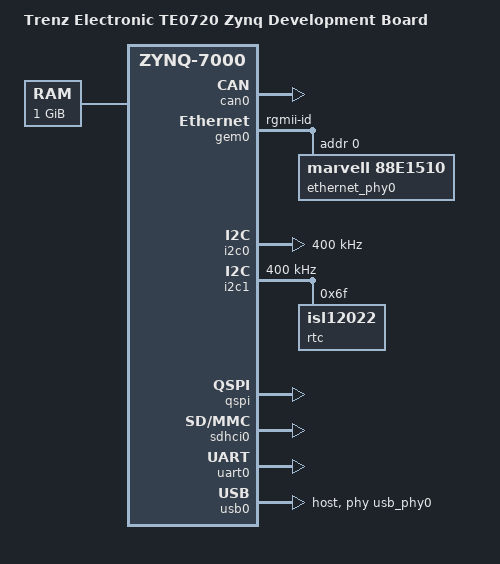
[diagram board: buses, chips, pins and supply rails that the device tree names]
/*
 * CAUTION: This file is automatically generated by Xilinx and post-processed by WB.
 * Version: HSI 2017.4
 * Today is: Wed Aug  7 14:38:01 2019
 */

/dts-v1/;
#include "zynq-7000.dtsi"

/ {
    model = "Trenz Electronic TE0720 Zynq Development Board";
    compatible = "xlnx,zynq-te0720", "xlnx,zynq-7000";

	chosen {
		bootargs = "";
		stdout-path = "serial0:115200n8";
	};
	aliases {
		ethernet0 = &gem0;
		i2c0 = &i2c0;
		i2c1 = &i2c1;
		serial0 = &uart0;
		spi0 = &qspi;
                mmc0 = &sdhci0;
	};
	memory@0 {
		device_type = "memory";
		reg = <0x0 0x40000000>;
	};
        usb_phy0: usb_phy@0 {
            compatible = "ulpi-phy";
            //compatible = "usb-nop-xceiv";
            #phy-cells = <0>;
            reg = <0xe0002000 0x1000>;
            view-port = <0x0170>;
            drv-vbus;
        };
};

&can0 {
	status = "okay";
};
&gem0 {
	enet-reset = <&gpio0 50 0>;
	phy-mode = "rgmii-id";
	status = "okay";
	xlnx,ptp-enet-clock = <0x69f6bcb>;
    	ethernet_phy0: ethernet-phy@0 {
		compatible = "marvell,88e1510";
		device_type = "ethernet-phy";
                reg = <0>;
	};
};
&gpio0 {
	emio-gpio-width = <64>;
	gpio-mask-high = <0x0>;
	gpio-mask-low = <0x5600>;
};
&i2c0 {
	clock-frequency = <400000>;
	status = "okay";
};
&i2c1 {
	clock-frequency = <400000>;
	status = "okay";
        rtc@6F {        // Real Time Clock
            compatible = "isl12022";
            reg = <0x6F>;
        };
};
&intc {
	num_cpus = <2>;
	num_interrupts = <96>;
};
&qspi {
        u-boot,dm-pre-reloc;
	is-dual = <0>;
	num-cs = <1>;
	spi-rx-bus-width = <4>;
	spi-tx-bus-width = <4>;
	status = "okay";
};
&sdhci0 {
        u-boot,dm-pre-reloc;
	status = "okay";
	xlnx,has-cd = <0x0>;
	xlnx,has-power = <0x0>;
	xlnx,has-wp = <0x0>;
};
&uart0 {
        u-boot,dm-pre-reloc;
	device_type = "serial";
	//port-number = <0>;
	status = "okay";
};
&usb0 {
	phy_type = "ulpi";
	status = "okay";
	usb-reset = <&gpio0 51 0>;
        dr_mode = "host";
        //dr_mode = "peripheral";
        usb-phy = <&usb_phy0>;
};
&clkc {
	fclk-enable = <0x1>;
	ps-clk-frequency = <33333333>;
};
